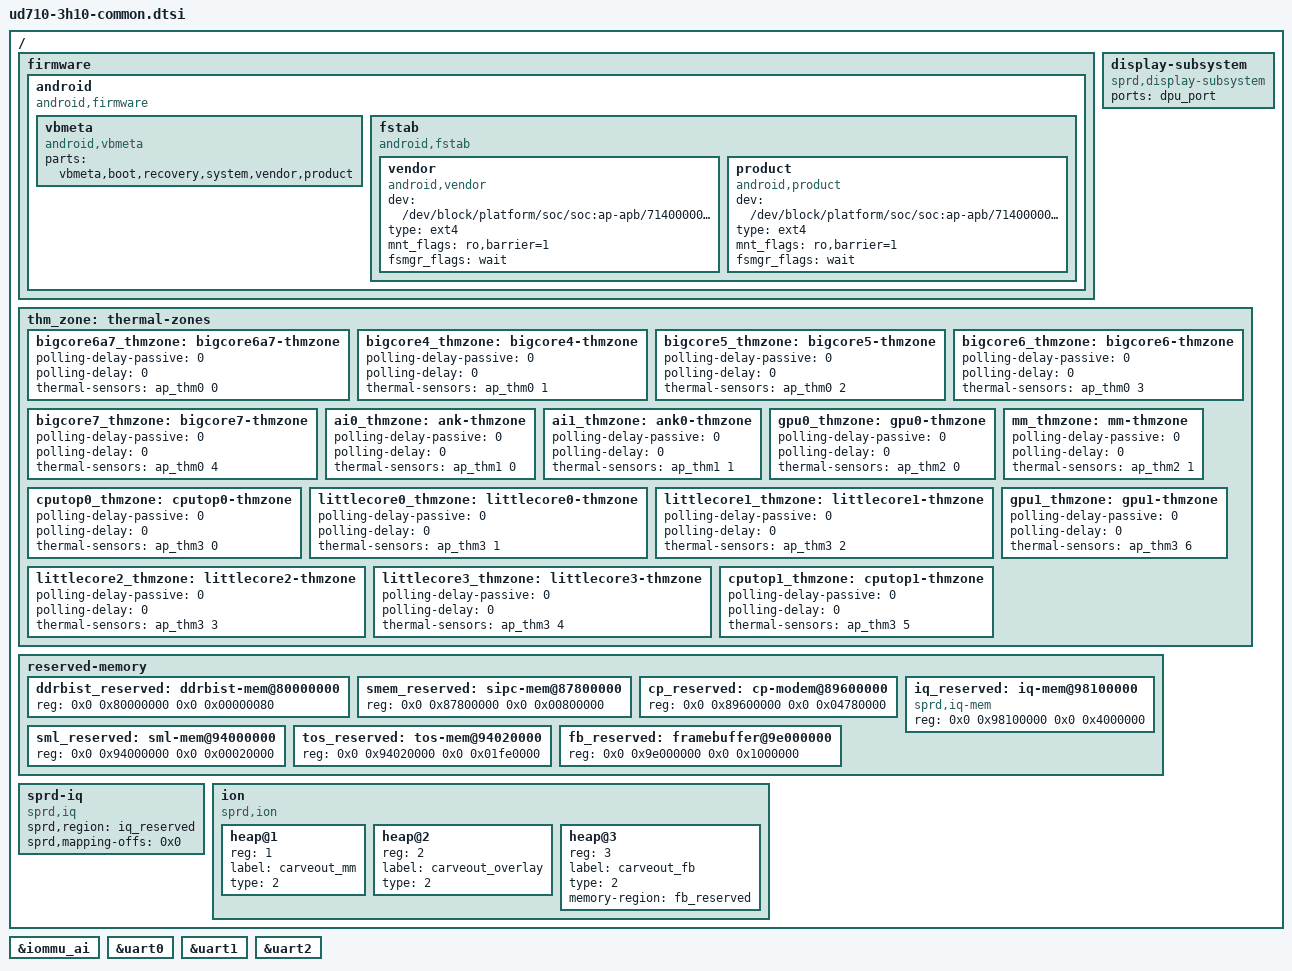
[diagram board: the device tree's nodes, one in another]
/*
 * Spreadtrum Roc1 board common DTS file
 *
 * Copyright (C) 2018, Spreadtrum Communications Inc.
 *
 * This file is licensed under a dual GPLv2 or X11 license.
 */

/ {
	firmware {
		android {
			compatible = "android,firmware";

			vbmeta {
				compatible = "android,vbmeta";
				parts = "vbmeta,boot,recovery,system,vendor,product";
			};

			fstab {
				compatible = "android,fstab";
				vendor {
					compatible = "android,vendor";
					dev = "/dev/block/platform/soc/soc:ap-apb/71400000.sdio/by-name/vendor";
					type = "ext4";
					mnt_flags = "ro,barrier=1";
					fsmgr_flags = "wait";
				};
				product {
					compatible = "android,product";
					dev = "/dev/block/platform/soc/soc:ap-apb/71400000.sdio/by-name/product";
					type = "ext4";
					mnt_flags = "ro,barrier=1";
					fsmgr_flags = "wait";
				};
			};
		};
	};

	display-subsystem {
		compatible = "sprd,display-subsystem";
		ports = <&dpu_port>;
	};

	thm_zone: thermal-zones {

		bigcore6a7_thmzone: bigcore6a7-thmzone {
			polling-delay-passive = <0>;
			polling-delay = <0>;
			thermal-sensors = <&ap_thm0 0>;
		};

		bigcore4_thmzone: bigcore4-thmzone {
			polling-delay-passive = <0>;
			polling-delay = <0>;
			thermal-sensors = <&ap_thm0 1>;
		};

		bigcore5_thmzone: bigcore5-thmzone {
			polling-delay-passive = <0>;
			polling-delay = <0>;
			thermal-sensors = <&ap_thm0 2>;
		};

		bigcore6_thmzone: bigcore6-thmzone {
			polling-delay-passive = <0>;
			polling-delay = <0>;
			thermal-sensors = <&ap_thm0 3>;
		};

		bigcore7_thmzone: bigcore7-thmzone {
			polling-delay-passive = <0>;
			polling-delay = <0>;
			thermal-sensors = <&ap_thm0 4>;
		};

		ai0_thmzone: ank-thmzone {
			polling-delay-passive = <0>;
			polling-delay = <0>;
			thermal-sensors = <&ap_thm1 0>;
		};

		ai1_thmzone: ank0-thmzone {
			polling-delay-passive = <0>;
			polling-delay = <0>;
			thermal-sensors = <&ap_thm1 1>;
		};

		gpu0_thmzone: gpu0-thmzone {
			polling-delay-passive = <0>;
			polling-delay = <0>;
			thermal-sensors = <&ap_thm2 0>;
		};

		mm_thmzone: mm-thmzone {
			polling-delay-passive = <0>;
			polling-delay = <0>;
			thermal-sensors = <&ap_thm2 1>;
		};

		cputop0_thmzone: cputop0-thmzone {
			polling-delay-passive = <0>;
			polling-delay = <0>;
			thermal-sensors = <&ap_thm3 0>;
		};

		littlecore0_thmzone: littlecore0-thmzone {
			polling-delay-passive = <0>;
			polling-delay = <0>;
			thermal-sensors = <&ap_thm3 1>;
		};

		littlecore1_thmzone: littlecore1-thmzone {
			polling-delay-passive = <0>;
			polling-delay = <0>;
			thermal-sensors = <&ap_thm3 2>;
		};

		littlecore2_thmzone: littlecore2-thmzone {
			polling-delay-passive = <0>;
			polling-delay = <0>;
			thermal-sensors = <&ap_thm3 3>;
		};

		littlecore3_thmzone: littlecore3-thmzone {
			polling-delay-passive = <0>;
			polling-delay = <0>;
			thermal-sensors = <&ap_thm3 4>;
		};

		cputop1_thmzone: cputop1-thmzone {
			polling-delay-passive = <0>;
			polling-delay = <0>;
			thermal-sensors = <&ap_thm3 5>;
		};

		gpu1_thmzone: gpu1-thmzone {
			polling-delay-passive = <0>;
			polling-delay = <0>;
			thermal-sensors = <&ap_thm3 6>;
		};
	};

	reserved-memory {
		#address-cells = <2>;
		#size-cells = <2>;
		ranges;

		ddrbist_reserved: ddrbist-mem@80000000{
			reg = <0x0 0x80000000 0x0 0x00000080>;
		};

		smem_reserved: sipc-mem@87800000{
			reg = <0x0 0x87800000 0x0 0x00800000>;
		};

		cp_reserved: cp-modem@89600000 {
			reg = <0x0 0x89600000 0x0 0x04780000>;
		};

		/* Only used for iq, will be removed in normal mode by uboot */
		iq_reserved: iq-mem@98100000{
			compatible = "sprd,iq-mem";
			reg = <0x0 0x98100000 0x0 0x4000000>;
		};

		sml_reserved: sml-mem@94000000{
			reg = <0x0 0x94000000 0x0 0x00020000>;
		};

		tos_reserved: tos-mem@94020000{
			reg = <0x0 0x94020000 0x0 0x01fe0000>;
		};

		fb_reserved: framebuffer@9e000000{
			reg = <0x0 0x9e000000 0x0 0x1000000>;
		};
	};

	sprd-iq {
			compatible = "sprd,iq";
			sprd,region = <&iq_reserved>;
			sprd,mapping-offs = <0x0>;
		};

	ion {
		compatible = "sprd,ion";
		#address-cells = <1>;
		#size-cells = <0>;

		heap@1 {
			reg = <1>;
			label = "carveout_mm";
			type = <2>;
		};

		heap@2 {
			reg = <2>;
			label = "carveout_overlay";
			type = <2>;
		};

		heap@3 {
			reg = <3>;
			label = "carveout_fb";
			type = <2>;
			memory-region = <&fb_reserved>;
		};
	};
};

&iommu_ai {
	status = "okay";
};

&uart0 {
	status = "okay";
};

&uart1 {
	status = "okay";
};

&uart2 {
	status = "okay";
};
